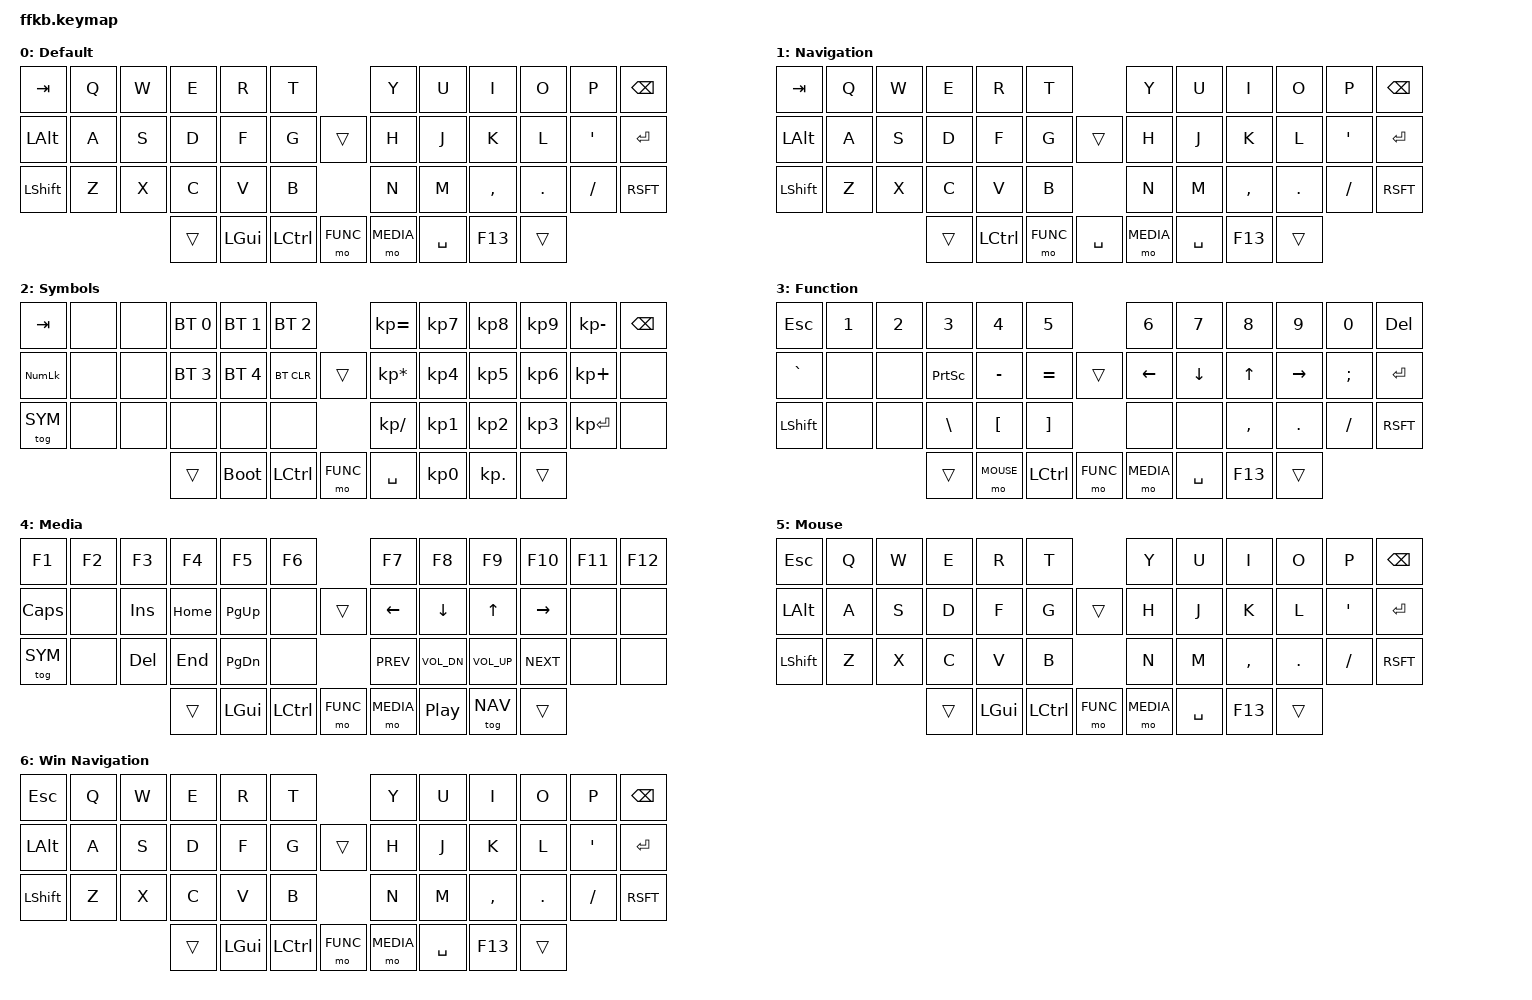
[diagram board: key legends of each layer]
#include <behaviors.dtsi>
#include <dt-bindings/zmk/keys.h>
#include <dt-bindings/zmk/rgb.h>
#include <dt-bindings/zmk/bt.h>
#include <dt-bindings/zmk/ext_power.h>
#include <dt-bindings/zmk/outputs.h>


#define DEFAULT 0
#define NAV     1
#define SYM     2
#define FUNC    3
#define MEDIA   4
#define MOUSE   5
#define WINNAV  6

&caps_word {
    continue-list = <UNDERSCORE MINUS>;
};

/ {
    combos {
        compatible = "zmk,combos";
        combo_undo {
            timeout-ms = <50>;
            key-positions = <26 27>;
            bindings = <&kp LC(Z)>;
        };
        combo_q {
            timeout-ms = <50>;
            key-positions = <27 28>;
            bindings = <&kp Q>;
        };
        combo_semicolon {
            timeout-ms = <50>;
            key-positions = <33 34>;
            bindings = <&kp SEMI>;
        };
    };
};

/ {

    sensors {
        compatible = "zmk,keymap-sensors";
        sensors = <&encoder_1 &encoder_2 &encoder_3>;
    };

    behaviors {
        hm: homerow_mods {
            compatible = "zmk,behavior-hold-tap";
            label = "HOMEROW_MODS";
            #binding-cells = <2>;
            tapping-term-ms = <200>;
            quick_tap_ms = <0>;
            flavor = "balanced";
            bindings = <&kp>, <&kp>;
        };
        hs: homerow_shift {
            compatible = "zmk,behavior-hold-tap";
            label = "HOMEROW_SHIFT";
            #binding-cells = <2>;
            tapping-term-ms = <175>;
            quick_tap_ms = <0>;
            flavor = "balanced";
            bindings = <&kp>, <&kp>;
        };
    };

    keymap {
        compatible = "zmk,keymap";

        default_layer {
            label = "Default";

            sensor-bindings = <&inc_dec_kp C_VOLUME_UP C_VOLUME_DOWN &inc_dec_kp C_VOLUME_UP C_VOLUME_DOWN &inc_dec_kp C_VOLUME_UP C_VOLUME_DOWN>;

            bindings = <
        &kp TAB    &kp Q        &kp W        &kp E       &kp R         &kp T                                       &kp Y         &kp U        &kp I         &kp O       &kp P       &kp BKSP
    &kp LALT   &kp A        &kp S        &kp D       &kp F         &kp G                &trans                 &kp H         &kp J        &kp K         &kp L       &kp QUOT    &kp ENTER
    &kp LSHIFT &kp Z        &kp X        &kp C       &kp V         &kp B                                       &kp N         &kp M        &kp CMMA      &kp DOT     &kp FSLH    &kp RSFT
                                         &trans      &kp LGUI      &kp LCTL      &mo FUNC      &mo MEDIA       &kp SPC       &kp F13      &trans
            >;
        };

        nav_layer {
            label = "Navigation";
            
            sensor-bindings = <&inc_dec_kp C_VOLUME_UP C_VOLUME_DOWN &inc_dec_kp C_VOLUME_UP C_VOLUME_DOWN>;
            
            bindings = <
    &kp TAB    &kp Q        &kp W        &kp E       &kp R         &kp T                                       &kp Y         &kp U        &kp I         &kp O       &kp P       &kp BKSP
    &kp LALT   &kp A        &kp S        &kp D       &kp F         &kp G                &trans                 &kp H         &kp J        &kp K         &kp L       &kp QUOT    &kp ENTER
    &kp LSHIFT &kp Z        &kp X        &kp C       &kp V         &kp B                                       &kp N         &kp M        &kp CMMA      &kp DOT     &kp FSLH    &kp RSFT
                                         &trans      &kp LCTL      &mo FUNC      &kp SPC       &mo MEDIA       &kp SPC       &kp F13      &trans
            >;
        };

        sym_layer {
            label = "Symbols";
            
            sensor-bindings = <&inc_dec_kp C_VOLUME_UP C_VOLUME_DOWN &inc_dec_kp C_VOLUME_UP C_VOLUME_DOWN>;
            
            bindings = <
    &kp TAB    &none        &none        &bt BT_SEL 0 &bt BT_SEL 1 &bt BT_SEL 2                                &kp KP_EQUAL  &kp KP_N7    &kp KP_N8     &kp KP_N9  &kp KP_MINUS &kp BKSP
    &kp KP_NLCK &none       &none        &bt BT_SEL 3 &bt BT_SEL 4 &bt BT_CLR                   &trans         &kp KP_ASTERISK &kp KP_N4  &kp KP_N5     &kp KP_N6   &kp KP_PLUS &none
    &tog SYM   &none        &none        &none       &none         &none                                       &kp KP_SLASH  &kp KP_N1    &kp KP_N2     &kp KP_N3   &kp KP_ENTER&none
                                         &trans      &bootloader   &kp LCTL      &mo FUNC      &kp SPC         &kp KP_N0     &kp KP_DOT   &trans
            >;
        };

        func_layer {
            label = "Function";

            sensor-bindings = <&inc_dec_kp C_VOLUME_UP C_VOLUME_DOWN &inc_dec_kp C_VOLUME_UP C_VOLUME_DOWN>;
            
            bindings = <
    &kp ESC    &kp N1       &kp N2       &kp N3      &kp N4        &kp N5                                      &kp N6        &kp N7       &kp N8        &kp N9      &kp N0      &kp DEL
    &kp GRAVE  &none        &none        &kp PSCRN   &kp MINUS     &kp EQUAL            &trans                 &kp LEFT      &kp DOWN     &kp UP        &kp RIGHT   &kp SEMI    &kp ENTER
    &kp LSHIFT &none        &none        &kp BSLH    &kp LBKT      &kp RBKT                                    &none         &none        &kp CMMA      &kp DOT     &kp FSLH    &kp RSFT
                                         &trans      &mo MOUSE     &kp LCTL      &mo FUNC      &mo MEDIA       &kp SPC       &kp F13      &trans
            >;
        };

        media_layer {
            label = "Media";
            
            sensor-bindings = <&inc_dec_kp C_VOLUME_UP C_VOLUME_DOWN &inc_dec_kp C_VOLUME_UP C_VOLUME_DOWN>;

            bindings = <
    &kp F1     &kp F2       &kp F3       &kp F4      &kp F5        &kp F6                                      &kp F7        &kp F8       &kp F9        &kp F10     &kp F11     &kp F12
    &kp CAPS   &none        &kp INS      &kp HOME    &kp PG_UP     &none                &trans                 &kp LEFT      &kp DOWN     &kp UP        &kp RIGHT   &none       &none
    &tog SYM   &none        &kp DEL      &kp END     &kp PG_DN     &none                                       &kp C_PREV    &kp C_VOL_DN &kp C_VOL_UP  &kp C_NEXT  &none       &none
                                         &trans      &kp LGUI      &kp LCTL      &mo FUNC      &mo MEDIA       &kp C_PP      &tog NAV     &trans
            >;
        };

        mouse_layer {
            label = "Mouse";
            
            sensor-bindings = <&inc_dec_kp C_VOLUME_DOWN C_VOLUME_UP &inc_dec_kp C_VOLUME_DOWN C_VOLUME_UP>;
            
            bindings = <
    &kp ESC    &kp Q        &kp W        &kp E       &kp R         &kp T                                       &kp Y         &kp U        &kp I         &kp O       &kp P       &kp BKSP
    &kp LALT   &kp A        &kp S        &kp D       &kp F         &kp G                &trans                 &kp H         &kp J        &kp K         &kp L       &kp QUOT    &kp ENTER
    &kp LSHIFT &kp Z        &kp X        &kp C       &kp V         &kp B                                       &kp N         &kp M        &kp COMMA     &kp DOT     &kp FSLH    &kp RSFT
                                         &trans      &kp LGUI      &kp LCTL      &mo FUNC      &mo MEDIA       &kp SPC       &kp F13      &trans
            >;
        };

        winnav_layer {
            label = "Win Navigation";
            
            sensor-bindings = <&inc_dec_kp C_VOLUME_UP C_VOLUME_DOWN &inc_dec_kp C_VOLUME_UP C_VOLUME_DOWN>;
            
            bindings = <
    &kp ESC    &kp Q        &kp W        &kp E       &kp R         &kp T                                       &kp Y         &kp U        &kp I         &kp O       &kp P       &kp BKSP
    &kp LALT   &kp A        &kp S        &kp D       &kp F         &kp G                &trans                 &kp H         &kp J        &kp K         &kp L       &kp QUOT    &kp ENTER
    &kp LSHIFT &kp Z        &kp X        &kp C       &kp V         &kp B                                       &kp N         &kp M        &kp COMMA     &kp DOT     &kp FSLH    &kp RSFT
                                         &trans      &kp LGUI      &kp LCTL      &mo FUNC      &mo MEDIA       &kp SPC       &kp F13      &trans
            >;
        };
    };
};
